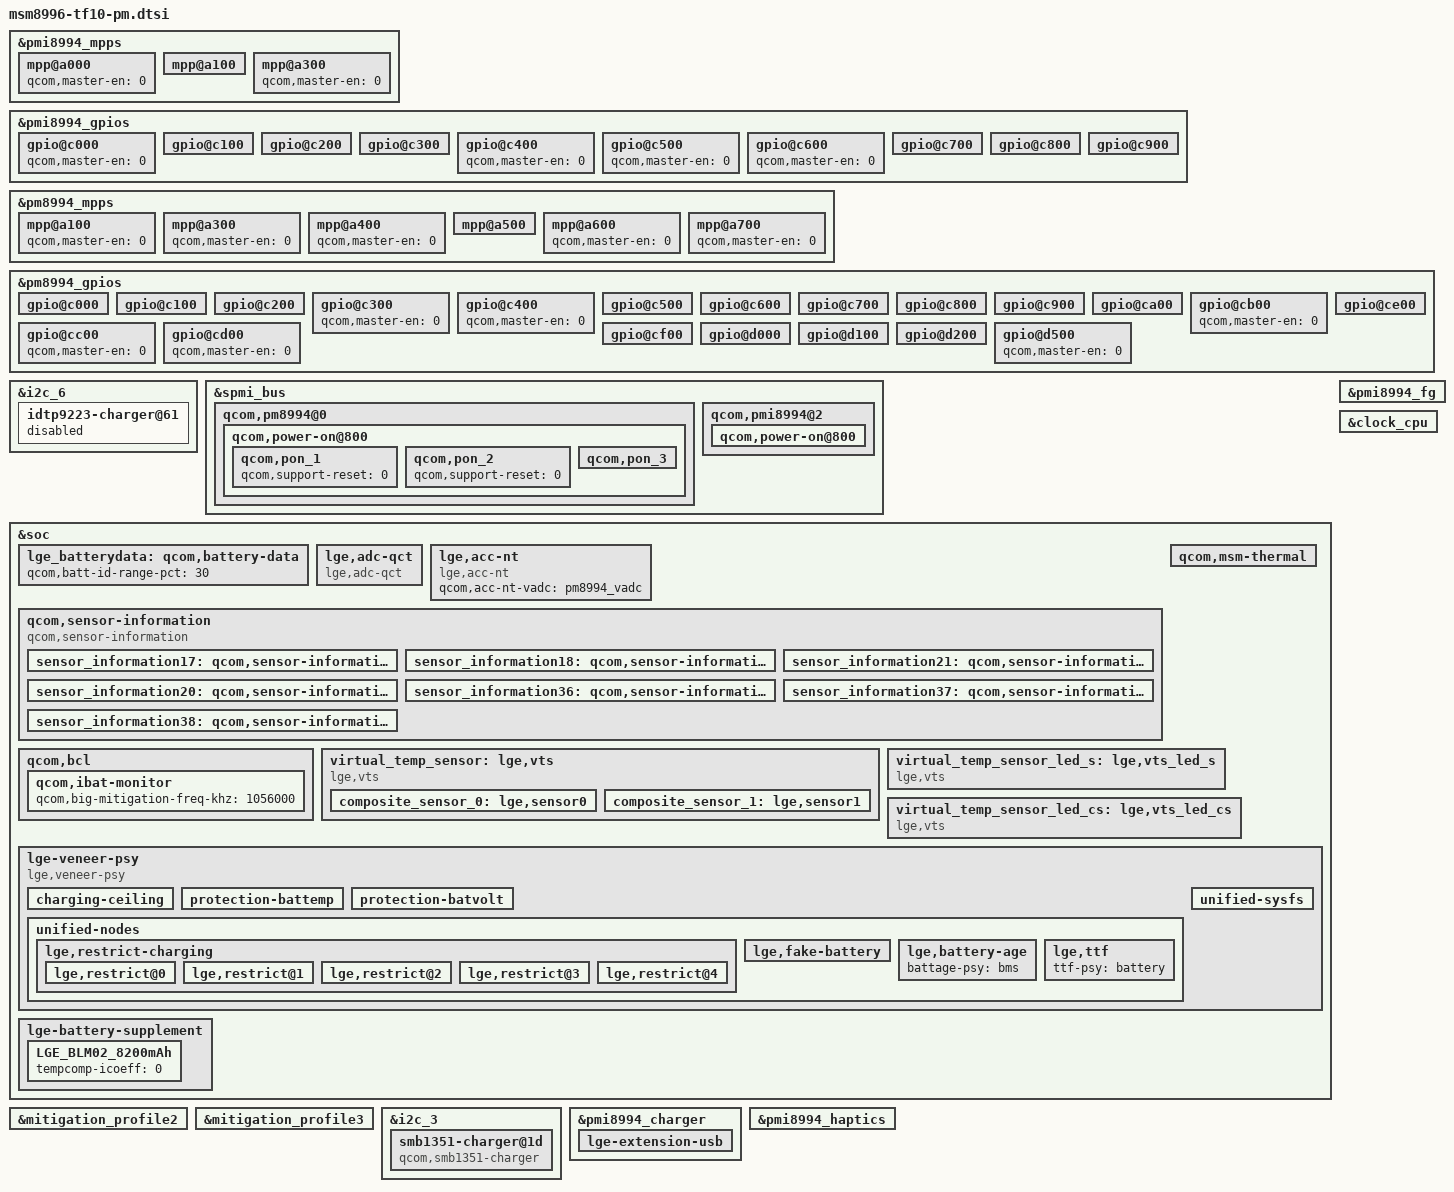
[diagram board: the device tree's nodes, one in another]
/* Copyright (c) 2015, The Linux Foundation. All rights reserved.
 *
 * This program is free software; you can redistribute it and/or modify
 * it under the terms of the GNU General Public License version 2 and
 * only version 2 as published by the Free Software Foundation.
 *
 * This program is distributed in the hope that it will be useful,
 * but WITHOUT ANY WARRANTY; without even the implied warranty of
 * MERCHANTABILITY or FITNESS FOR A PARTICULAR PURPOSE.  See the
 * GNU General Public License for more details.
 */

&pmi8994_mpps {
/* Must not define the mpp(mpp 3) on here */
	mpp@a000 {	/* MPP 1 - NC */
		qcom,master-en = <0>;		/* Disable MPP */
		status = "okay";
	};

	mpp@a100 { /* MPP 2 - FLASH_STROBE_TRIG */
		qcom,mode = <0>;			/* Digital input */
		qcom,invert = <1>;			/* Enable invert */
		qcom,vin-sel = <2>;			/* Vin 2 */
		qcom,src-sel = <0>;			/* Constant */
		qcom,master-en = <1>;		/* Enable MPP */
		status = "okay";
	};

	mpp@a300 { /* MPP 4 - NC */
		qcom,master-en = <0>;		/* Disable MPP */
		status = "okay";
	};
};

&pmi8994_gpios {
	gpio@c000 { /* GPIO 1 - NC */
		qcom,master-en = <0>;		/* Disable GPIO */
		status = "okay";
	};

	gpio@c100 { /* GPIO 2 - HIFI_RESET_N */
		qcom,mode = <1>;			/* Digital output*/
		qcom,pull = <0>;			/* Pull down 30uA */
		qcom,vin-sel = <2>;			/* VIN2 */
		qcom,src-sel = <0>;			/* Constant */
		qcom,invert = <1>;			/* Enable Invert */
		qcom,out-strength = <1>;	/* Low */
		qcom,master-en = <1>;		/* Enable GPIO */
		status = "okay";
	};

	gpio@c200 {	/* GPIO 3 SPKR_AMP_EN2 */
		qcom,mode = <1>;			/* Digital output*/
		qcom,pull = <4>;			/* Pull down */
		qcom,vin-sel = <2>;			/* VIN2 */
		qcom,src-sel = <0>;			/* Constant */
		qcom,invert = <0>;			/* Disable Invert */
		qcom,out-strength = <1>;	/* Low */
		qcom,master-en = <1>;		/* Enable GPIO */
		status = "okay";
	};

	gpio@c300 { /* GPIO 4 - WLC_OFF */
		qcom,mode = <1>;			/* Digital output*/
		qcom,pull = <4>;			/* Pull down */
		qcom,vin-sel = <2>;			/* VIN2 */
		qcom,src-sel = <0>;			/* Constant */
		qcom,invert = <0>;			/* Disable Invert */
		qcom,out-strength = <1>;	/* Low */
		qcom,master-en = <1>;		/* Enable GPIO */
		status = "okay";
	};

	gpio@c400 { /* GPIO 5 - NC */
		qcom,master-en = <0>;		/* Disable GPIO */
		status = "okay";
	};

	gpio@c500 { /* GPIO 6 - NC */
		qcom,master-en = <0>;		/* Disable GPIO */
		status = "okay";
	};

	gpio@c600 { /* GPIO 7 - NC */
		qcom,master-en = <0>;		/* Disable GPIO */
		status = "okay";
	};

	gpio@c700 { /* GPIO 8 - NC */
		qcom,master-en = <0>;		/* Disable GPIO */
		status = "okay";
	};

	gpio@c800 { /* GPIO 9 - NC */
		qcom,master-en = <0>;		/* Disable GPIO */
		status = "okay";
	};

	gpio@c900 { /* GPIO 10 - NC */
		qcom,master-en = <0>;		/* Disable GPIO */
		status = "okay";
	};
};

&pmi8994_gpios {
	gpio@c300 { /* GPIO 4 - NC */
		qcom,master-en = <0>;		/* Disable GPIO */
		status = "okay";
	};

	gpio@c700 {
	  qcom,mode = <1>;
	  qcom,pull = <4>;
	  qcom,vin-sel = <2>;
	  qcom,src-sel = <0>;
	  qcom,invert = <0>;
	  qcom,master-en = <1>;
	  status = "okay";
	 };

	gpio@c800 {
	  qcom,mode = <1>;
	  qcom,output-type = <0>;
	  qcom,invert = <1>;
	  qcom,vin-sel = <0>;
	  qcom,src-sel = <0>;
	  qcom,out-strength = <1>;
	  qcom,master-en = <1>;
	  status = "okay";
	 };

	 gpio@c900 {
	  qcom,mode = <0>;
	  qcom,vin-sel = <2>;
	  qcom,src-sel = <0>;
	  qcom,master-en = <1>;
	  status = "okay";
	 };

};

&pm8994_mpps {
/* Must not define the mpps(mpp 1 and 3) on here */
	mpp@a100 { /* MPP 2 - NC */
		qcom,master-en = <0>;		/* Disable MPP */
		status = "okay";
	};

	mpp@a300 { /* MPP 4 - NC */
		qcom,master-en = <0>;		/* Disable MPP */
		status = "okay";
	};

	mpp@a400 { /* MPP 5 - NC */
		qcom,master-en = <0>;		/* Disable MPP */
		status = "okay";
	};

	mpp@a500 { /* MPP 6 - STAT_SMB1350 */
		qcom,mode = <1>;			/* Digital output */
		qcom,invert = <0>;			/* Enable invert */
		qcom,vin-sel = <2>;			/* Vin 2 */
		qcom,src-sel = <0>;			/* Constant */
		qcom,out-strength = <1>;	/* Low */
		qcom,master-en = <1>;		/* Enable MPP */
		status = "okay";
	};

	mpp@a600 { /* MPP 7 - NC */
		qcom,master-en = <0>;		/* Disable MPP */
		status = "okay";

	};

	mpp@a700 { /* MPP 8 - NC */
		qcom,master-en = <0>;		/* Disable MPP */
		status = "okay";
	};
};

&pm8994_gpios {
/* Gpio 1 and 3 is set on relevant usb-type-c */
/* Must not define the gpios(gpio 20 and 21) on here */
	gpio@c000 { /* GPIO 1 VCONN */
		qcom,mode = <1>;		/* Digital output */
		qcom,pull = <0>;
		qcom,vin-sel = <2>;		/* VIN2 */
		qcom,src-sel = <2>;		/* GPIO */
		qcom,master-en = <1>;		/* Enable GPIO */
		status = "okay";
	};

	gpio@c100 { /* GPIO 2 - VOL_UP_EN */
		qcom,mode = <0>;			/* Digital input */
		qcom,pull = <0>;			/* Pull up 30uA */
		qcom,vin-sel = <2>;			/* Vin 2 */
		qcom,src-sel = <0>;			/* Constant */
		qcom,invert = <1>;			/* Enable Invert */
		qcom,out-strength = <1>;	/* Low */
		qcom,master-en = <1>;		/* Enable GPIO */
		status = "okay";
	};

	gpio@c200 { /* GPIO 3 SBU_SEL */
		qcom,mode = <1>;		/* Digital output */
		qcom,output-type = <0>;		/* MOS logic */
		qcom,vin-sel = <0>;		/* VPH_PWR */
		qcom,src-sel = <0>;		/* Constant */
		qcom,out-strength = <1>;	/* High drive strength */
		qcom,master-en = <1>;		/* Enable GPIO */
		status = "okay";
	};

	gpio@c300 { /* GPIO 4 - NC */
		qcom,master-en = <0>;		/* Disable GPIO */
		status = "okay";
	};

	gpio@c400 { /* GPIO 5 - NC */
		qcom,master-en = <0>;		/* Disable GPIO */
		status = "okay";
	};

	gpio@c500 { /* GPIO 6 - CAM0_AVDD_EN */
		qcom,mode = <1>;			/* Digital output */
		qcom,pull = <4>;			/* Pull down */
		qcom,vin-sel = <2>;			/* Vin 2 */
		qcom,src-sel = <0>;			/* Constant */
		qcom,invert = <0>;			/* Disable Invert */
		qcom,out-strength = <1>;	/* Low */
		qcom,master-en = <1>;		/* Enable GPIO */
		status = "okay";
	};

	gpio@c600 { /* GPIO 7 - CAM1_AVDD_EN */
		qcom,mode = <1>;			/* Digital output */
		qcom,pull = <4>;			/* Pull down */
		qcom,vin-sel = <2>;			/* Vin 2 */
		qcom,src-sel = <0>;			/* Constant */
		qcom,invert = <0>;			/* Disable Invert */
		qcom,out-strength = <1>;	/* Low */
		qcom,master-en = <1>;		/* Enable GPIO */
		status = "okay";
	};

	gpio@c700 { /* GPIO 8 - WLAN_POWER_EN */
		qcom,mode = <1>;			/* Digital output */
		qcom,pull = <4>;			/* Pull down */
		qcom,output-type = <0>;		/* CMOS logic */
		qcom,vin-sel = <2>;			/* Vin2 */
		qcom,src-sel = <0>;			/* Constant */
		qcom,invert = <0>;			/* Disable Invert */
		qcom,out-strength = <1>;	/* Low */
		qcom,master-en = <1>;		/* Enable GPIO */
		status = "okay";
	};

	gpio@c800 { /* GPIO 9 - Rome 3.3V control */
		qcom,mode = <1>;		/* Digital output */
		qcom,output-type = <0>;		/* CMOS logic */
		qcom,invert = <1>;		/* Output high */
		qcom,vin-sel = <0>;		/* VPH_PWR */
		qcom,src-sel = <0>;		/* Constant */
		qcom,out-strength = <1>;	/* High drive strength */
		qcom,master-en = <1>;		/* Enable GPIO */
		status = "okay";
	};

	gpio@c900 { /* GPIO 10 - HIFI_MODE2 */
		qcom,mode = <1>;			/* Digital output */
		qcom,pull = <4>;			/* Pull down */
		qcom,vin-sel = <2>;			/* Vin2 */
		qcom,src-sel = <0>;			/* Constant */
		qcom,invert = <0>;			/* Disable Invert */
		qcom,out-strength = <1>;	/* Low */
		qcom,master-en = <1>;		/* Enable GPIO */
		status = "okay";
	};

	gpio@ca00 { /* GPIO 11 - HIFI_LDO_SW */
		qcom,mode = <1>;			/* Digital output */
		qcom,pull = <4>;			/* Pull down */
		qcom,vin-sel = <2>;			/* Vin 2 */
		qcom,src-sel = <0>;			/* Constant */
		qcom,invert = <0>;			/* Invert */
		qcom,out-strength = <1>;	/* Low */
		qcom,master-en = <1>;		/* Enable GPIO */
		status = "okay";
	};

	gpio@cb00 { /* GPIO 12 - NC */
		qcom,master-en = <0>;		/* Disable GPIO */
		status = "okay";
	};

	gpio@cc00 { /* GPIO 13 - NC */
		qcom,master-en = <0>;		/* Disable GPIO */
		status = "okay";
	};

	gpio@cd00 { /* GPIO 14 - NC */
		qcom,master-en = <0>;		/* Disable GPIO */
		status = "okay";
	};

	gpio@ce00 { /* GPIO 15 - CODEC_MCLK */
		qcom,mode = <1>;			/* Digital output */
		qcom,pull = <5>;			/* No pull */
		qcom,output-type = <0>;		/* CMOS logic */
		qcom,vin-sel = <2>;			/* Vin 2 */
		qcom,src-sel = <2>;			/* Function 2 */
		qcom,out-strength = <2>;	/* Middle */
		qcom,master-en = <1>;		/* Enable GPIO */
		status = "okay";
	};

	gpio@cf00 { /* GPIO 16 - PMI_CLK_IN */
		qcom,mode = <1>;			/* Digital output */
		qcom,pull = <5>;			/* No pull */
		qcom,output-type = <0>;		/* CMOS logic */
		qcom,vin-sel = <2>;			/* Vin 2 */
		qcom,src-sel = <2>;			/* Function 2 */
		qcom,invert = <0>;			/* Disable Invert */
		qcom,out-strength = <3>;	/* High */
		qcom,master-en = <1>;		/* Enable GPIO */
		status = "okay";
	};

	gpio@d000 { /* GPIO 17 - AOD_RTC */
		qcom,mode = <1>;			/* Digital output */
		qcom,pull = <5>;			/* No pull */
		qcom,output-type = <0>;		/* CMOS logic */
		qcom,vin-sel = <2>;			/* Vin 2 */
		qcom,src-sel = <3>;			/* Function 2 */
		qcom,out-strength = <2>;	/* Middle */
		qcom,master-en = <1>;		/* Enable GPIO */
		status = "okay";
	};

	gpio@d100 { /* GPIO 18 - WIFI_SLEEP_CLK */
		qcom,mode = <1>;			/* Digital output */
		qcom,output-type = <0>;		/* CMOS logic */
		qcom,invert = <0>;			/* Output low initially */
		qcom,vin-sel = <2>;			/* VIN 2 */
		qcom,src-sel = <3>;			/* Function 2 */
		qcom,out-strength = <2>;	/* Medium */
		qcom,master-en = <1>;		/* Enable GPIO */
		status = "okay";
	};

	gpio@d200 { /* GPIO 19 - BT_POWER_ON */
		qcom,mode = <1>;			/* Digital output */
		qcom,pull = <4>;			/* Pull down */
		qcom,vin-sel = <2>;			/* Vin2 */
		qcom,src-sel = <0>;			/* Constant */
		qcom,invert = <0>;			/* Disable Invert */
		qcom,out-strength = <1>;	/* Low */
		qcom,master-en = <1>;		/* Enable GPIO */
		status = "okay";
	};
	gpio@d500 { /* GPIO 22 - NC */
		qcom,master-en = <0>;		/* Disable GPIO */
		status = "okay";
	};
};

&i2c_6 {
        idtp9223-charger@61 {
                status = "disabled";
        };
};

&spmi_bus {
	qcom,pm8994@0 {
		 qcom,power-on@800 {
			 qcom,s3-debounce = <128>;
			 qcom,s3-src = "kpdpwr-and-resin";
			 qcom,pon_1 {  /* KPD_PWR_N */
				  status = "ok";
				  qcom,support-reset = <0>;
			 };
			 qcom,pon_2 {  /* RESIN_N */
				  status = "ok";
				  qcom,support-reset = <0>;
			 };
			 qcom,pon_3 {  /* KPD_PWR_N AND RESIN_N */
				  status = "ok";
				  qcom,support-reset = <1>;
				  qcom,s1-timer = <6720>;
				  qcom,s2-timer = <2000>;
				  qcom,s2-type = <7>;
			 };
		 };
	};

	qcom,pmi8994@2 {
		qcom,power-on@800 {
			qcom,s3-debounce = <128>;
			qcom,s3-src = "kpdpwr-and-resin";
		};
	};
};

&soc {
	lge_batterydata: qcom,battery-data {
		qcom,batt-id-range-pct = <30>;
		#include "../LGE_BLM02_8200mAh.dtsi"
	};

	lge,adc-qct {
		compatible = "lge,adc-qct";
		qcom,pm_adc-vadc = <&pm8994_vadc>;
		qcom,pmi_adc-vadc = <&pmi8994_vadc>;
		lge,gpio-sbu-en = <&tlmm 90 0>;
		lge,xo_therm_chan = <0x72>;
		lge,pa0_therm_chan = <0x75>;
		lge,pa1_therm_chan = <0x77>;
		lge,bd1_therm_chan = <0xff>;
		lge,bd2_therm_chan = <0x74>;
		lge,batt_therm_chan = <0xff>;
		lge,usb_id_chan = <0x39>;
	};

	lge,acc-nt {
		compatible = "lge,acc-nt";
		qcom,acc-nt-vadc = <&pm8994_vadc>;
	};

	qcom,sensor-information {
		compatible = "qcom,sensor-information";

		sensor_information17: qcom,sensor-information-17 {
			qcom,sensor-type = "adc";
			qcom,sensor-name = "bd_therm_1";
		};

		sensor_information18: qcom,sensor-information-18 {
			qcom,sensor-type = "adc";
			qcom,sensor-name = "bd_therm_2";
		};

		sensor_information21: qcom,sensor-information-21 {
			qcom,sensor-type = "adc";
			qcom,sensor-name = "xo_therm";
		};
		sensor_information20: qcom,sensor-information-20 {
			qcom,sensor-type = "adc";
			qcom,sensor-name = "vts";
			qcom,scaling-factor = <10>;
		};
		sensor_information36: qcom,sensor-information-36 {
			qcom,sensor-type = "adc";
			qcom,sensor-name = "battery";
			qcom,scaling-factor = <1000>;
		};
		sensor_information37: qcom,sensor-information-37 {
			qcom,sensor-type = "adc";
			qcom,sensor-name = "led_sensor";
			qcom,scaling-factor = <1>;
		};

		sensor_information38: qcom,sensor-information-38 {
			qcom,sensor-type = "adc";
			qcom,sensor-name = "led_c_sensor";
			qcom,scaling-factor = <1>;
		};
	};

	qcom,msm-thermal {
		qcom,poll-ms = <50>;
		qcom,limit-temp = <80>;
		qcom,core-limit-temp = <90>;
		qcom,disable-gfx-phase-ctrl;
		qcom,disable-psm;
		qcom,disable-ocr;
		qcom,disable-cx-phase-ctrl;
		qcom,freq-mitigation-temp = <103>;
		qcom,freq-mitigation-temp-hysteresis = <15>;
		qcom,freq-mitigation-value = <1036800>;
		qcom,big-hotplug-temp = <105>;
		qcom,big-hotplug-temp-hysteresis = <40>;
	};

	qcom,bcl {
		qcom,bcl-soc-hotplug-list = <>;
		qcom,bcl-freq-control-list = <&CPU0 &CPU1 &CPU2 &CPU3>;
	};

	/* vts, 0.620*XO + 0.116*BD2 + 6.94 */
	virtual_temp_sensor: lge,vts {
		compatible = "lge,vts";
		lge,index = <101>;
		qcom,vts-vadc = <&pm8994_vadc>;
		lge,scaling-factor = <10>;
		lge,constant-milli = <6940>;
		composite_sensor_0: lge,sensor0 {
			label = "xo_therm";
			channel = <0x72>;
			weight-milli = <620>;
		};
		composite_sensor_1: lge,sensor1 {
			label = "bd_therm_2";
			channel = <0x74>;
			weight-milli = <116>;
		};
	};

	virtual_temp_sensor_led_s: lge,vts_led_s {
		compatible = "lge,vts";
		lge,name = "led_sensor";
		lge,index = <102>;
		qcom,vts-vadc = <&pm8994_vadc>;
		lge,scaling-factor= <1>;
	};

	virtual_temp_sensor_led_cs: lge,vts_led_cs {
		compatible = "lge,vts";
		lge,name = "led_c_sensor";
		lge,index = <103>;
		qcom,vts-vadc = <&pm8994_vadc>;
		lge,scaling-factor= <1>;
	};

};

&mitigation_profile2 {
	qcom,temperature-sensor = <&sensor_information9>;
	qcom,boot-frequency-mitigate;
	qcom,hotplug-mitigation-enable;
};

&mitigation_profile3 {
	qcom,temperature-sensor = <&sensor_information11>;
	qcom,boot-frequency-mitigate;
	qcom,hotplug-mitigation-enable;
};

&soc {
        qcom,msm-thermal {
                qcom,freq-mitigation-value = <1056000>;
        };
        qcom,bcl {
                qcom,ibat-monitor {
                        qcom,big-mitigation-freq-khz = <1056000>;
                };
        };
};

&soc {
    lge-veneer-psy {
        compatible = "lge,veneer-psy";
        status = "ok";

        charging-ceiling {
            /*             iusb ibat  : 0 means UNCEILING */
            lge,unknown = <   0    0>;
            lge,float   = < 500  500>;
            lge,none    = <   0    0>;

            lge,dcp     = <1800 3000>;
            lge,10k     = <3000    0>;
            lge,22k     = <1500    0>;
            lge,qc2     = <1800 3000>;
            lge,qc3     = <1800 3000>;

            lge,usb2    = < 500  500>;
            lge,usb3    = < 900  900>;
            lge,cdp     = <1500 1500>;
            lge,pd      = <   0    0>;

            lge,56k     = <1500  500>;
            lge,130k    = <1500  500>;
            lge,910k    = <1500  500>;
        };

        protection-battemp {
            lge,threshold-degc-upto-cool = <30>;
            lge,threshold-degc-upto-good = <120>;
            lge,threshold-degc-upto-warm = <450>;
            lge,threshold-degc-upto-hot = <550>;
            lge,threshold-degc-downto-warm = <520>;
            lge,threshold-degc-downto-good = <430>;
            lge,threshold-degc-downto-cool = <100>;
            lge,threshold-degc-downto-cold = <0>;

            lge,period-ms-emergency = <10000>;
            lge,period-ms-warning   = <30000>;
            lge,period-ms-normal    = <60000>;

            // parameters for warning status cool and warm
            lge,cool-mv-alert   = <4000>;
            lge,cool-ma-alert   = <800>;        // fixed 500 mA over 4V(0.2C)   // tf10 fixed 800mA            (0.1C)
            lge,cool-ma-pct     = <10>;         // means 0.1C rate under 4V     // tf10 cool ibat set to 800mA (0.1C)

            lge,warm-mv-float   = <4000>;
            lge,warm-ma-pct     = <10>;         // means 0.1C rate under 4V     // tf10 warm ibat set to 800mA (0.1C)

            // parameters for battery protection at chilly status
            lge,chilly-status-support;
            lge,chilly-degc-lowerbound = <100>;
            lge,chilly-degc-upperbound = <150>;
            lge,chilly-mv-alert    = <4000>;
            lge,chilly-mv-bound     = <200>;
            lge,chilly-ma-alert    = <2400>;    // fixed 2400mA over 4V         // tf10 fixed 550mA             (0.2C)
            lge,chilly-ma-pct      = <30>;      // means 0.3C rate under 4V     // tf10 chilly ibat set to 2400mA (0.4C)
        };

        protection-batvolt {
            lge,threshold-vbat-limit = <4250>;
            lge,threshold-vbat-clear = <4200>;
	    lge,threshold-ibat-pct = <70>;	// means 0.7C rate
	    lge,threshold-cv-ibat-pct = <100>;	// means 0.1C rate

            lge,step-ibat-ma = <100>;
            lge,step-poll-ms = <5000>;
        };

        unified-nodes {
            lge,feature-charging-parallel = <0>;
            lge,feature-charging-highspeed = <0>;

            lge,restrict-charging {
                // restrict-values 0 means UNCEILING

                lge,restrict@0 {
                    restrict-name = "LCD";
                    restrict-type = "ibat";
                    restrict-commands = "ON", "OFF";
                    restrict-values = <1800      0>;
                };
                lge,restrict@1 {
                    restrict-name = "CALL";
                    restrict-type = "ibat";
                    restrict-commands = "ON", "OFF";
                    restrict-values = < 0      0>;
                };
                lge,restrict@2 {
                    restrict-name = "UHDREC";
                    restrict-type = "ibat";
                    restrict-commands = "ON", "OFF";
                    restrict-values = < 0      0>;
                };
                lge,restrict@3 {
                    restrict-name = "WFD";
                    restrict-type = "ibat";
                    restrict-commands = "ON", "OFF";
                    restrict-values = < 0      0>;
                };
                lge,restrict@4 {
                    restrict-name = "TDMB";
                    restrict-type = "ibat";
                    restrict-commands = "MODE1", "MODE2", "OFF";
                    restrict-values = <    0      0      0>;
                };
            };

            lge,fake-battery {
                fakebatt-psy = "bms";       // What 'psy' does implement(or support) the fake battery?
                fakebatt-temperature = <400>;
                fakebatt-mvoltage = <4000>;
                fakebatt-capacity = <80>;
            };

            lge,battery-age {
                battage-psy = "bms";        // What 'psy' does implement(or support) the battery age?
            };

            lge,ttf {
                ttf-psy = "battery";	// What 'psy' does implement(or support) the time to full now?
            };
        };

        unified-sysfs {
            lge,symlink-map =
                /* group , user_node, kernel node */
                /* Charger */
                "charger",                     "ac_online", "NULL",
                "charger",                    "usb_online", "/sys/class/power_supply/usb/online",   /* TODO */
                "charger",                       "present", "/sys/class/power_supply/usb/present",
                "charger",                    "wlc_online", "/sys/class/power_supply/wireless/online",
                "charger",                          "type", "/sys/class/power_supply/usb/real_type",
		"charger",                   "usb_pd_type", "/sys/class/power_supply/usb/real_type",
                "charger",                      "time_out", "/sys/class/power_supply/battery/safety_timer_enabled",
                "charger",              "charging_enabled", "/sys/devices/platform/lge-unified-nodes/charging_enable",
                "charger",                  "ibat_current", "/sys/class/power_supply/battery/current_now",
                "charger",                  "ichg_current", "/sys/class/power_supply/usb/current_max",
                "charger",                  "iusb_control", "NULL",
                "charger",            "thermal_mitigation", "NULL",
                "charger",        "wlc_thermal_mitigation", "NULL",
                "charger",       "usb_parallel_chg_status", "NULL",
				"charger", "parallel_current_max", "/sys/class/power_supply/parallel/current_max",
                "charger", "usb_parallel_charging_enabled", "NULL",
                "charger", "factory_parallel_charger_test", "/sys/devices/platform/lge-unified-nodes/support_fastpl",
                "charger",            "moisture_detection", "/sys/class/power_supply/usb/moisture_detected",
                "charger",           "restricted_charging", "/sys/devices/platform/lge-unified-nodes/charging_restriction",
                "charger",              "ibat_max_current", "/sys/class/power_supply/battery/constant_charge_current_max",
                "charger",                       "chgstep", "/sys/devices/platform/lge-unified-nodes/charging_step",
                "charger",               "connection_type", "NULL",
                "charger",                       "fastchg", "/sys/devices/platform/lge-unified-nodes/charger_highspeed",
                "charger",         "input_current_settled", "/sys/class/power_supply/battery/input_current_max",
                "charger",             "input_current_max", "/sys/class/power_supply/battery/input_current_max",
                "charger",            "store_demo_enabled", "NULL",
                "charger",     "wireless_charging_enabled", "NULL",
                "charger",                 "input_suspend", "/sys/class/power_supply/battery/input_suspend",
                "charger",                  "incompatible", "/sys/devices/platform/lge-unified-nodes/charger_incompatible",
                "charger",                    "hvdcp_fake", "/sys/devices/platform/lge-unified-nodes/fake_hvdcp",
                "charger",               "usb_current_max", "/sys/devices/platform/lge-unified-nodes/fake_sdpmax",
                "charger",               "fastchg_support", "/sys/devices/platform/lge-unified-nodes/support_fastchg",
                "charger",                    "usbid_type", "/sys/class/power_supply/usb/resistance_id",
                "charger",                 "ccd_batchg_en", "/sys/devices/platform/lge-unified-nodes/ccd_batchg_en",
                "charger",             "ccd_input_suspend", "/sys/devices/platform/lge-unified-nodes/ccd_input_suspend",
                "charger",                       "ccd_icl", "/sys/devices/platform/lge-unified-nodes/ccd_icl",
                "charger",                       "ccd_fcc", "/sys/devices/platform/lge-unified-nodes/ccd_fcc",
                "charger",                    "ccd_vfloat", "/sys/devices/platform/lge-unified-nodes/ccd_vfloat",
                "charger",                     "aicl_done", "/sys/devices/platform/lge-unified-nodes/aicl_done",
                /* ADC/MPP */
                "adc",              "thermal", "/sys/class/thermal/",
                "adc",             "xo_therm", "/sys/class/hwmon/hwmon2/device/xo_therm",
                "adc",           "batt_therm", "/sys/class/power_supply/battery/temp",
                "adc",              "batt_id", "/sys/devices/platform/lge-unified-nodes/battery_valid",
                "adc",            "pa_therm0", "/sys/class/hwmon/hwmon2/device/pa_therm0",
                "adc",            "pa_therm1", "NULL",
                "adc",           "quiet_therm","/sys/class/hwmon/hwmon2/device/quiet_therm",
                "adc",               "usb_in", "/sys/class/power_supply/usb/voltage_now",
                "adc",                "vcoin", "/sys/class/hwmon/hwmon2/device/vcoin",
                "adc",              "vph_pwr", "/sys/class/hwmon/hwmon2/device/vph_pwr",
                "adc",               "usb_id", "/sys/devices/platform/lge-unified-nodes/charger_usbid",
                "adc",             "usb_edge", "NULL",
                "adc",                 "pmic", "/sys/class/thermal/thermal_zone2/temp",
                "adc",                  "vts", "/sys/class/thermal/thermal_zone38/temp",
                /* Battery */
                "battery",         "capacity", "/sys/class/power_supply/battery/capacity",
                "battery",           "health", "/sys/class/power_supply/battery/health",
                "battery",          "present", "/sys/class/power_supply/battery/present",
                "battery",      "pseudo_batt", "/sys/devices/platform/lge-unified-nodes/fake_battery",
                "battery",           "status", "/sys/class/power_supply/battery/status",
                "battery",       "status_raw", "NULL",
                "battery",             "temp", "/sys/class/power_supply/battery/temp",
                "battery",    "valid_batt_id", "/sys/devices/platform/lge-unified-nodes/battery_valid",
                "battery",      "voltage_now", "/sys/class/power_supply/battery/voltage_now",
                "battery",          "vzw_chg", "/sys/devices/platform/lge-unified-nodes/charger_verbose",
                "battery",     "raw_capacity", "/sys/class/power_supply/bms/capacity",
                "battery",        "condition", "/sys/devices/platform/lge-unified-nodes/battery_condition",
                "battery",      "battery_age", "/sys/devices/platform/lge-unified-nodes/battery_age",
                "battery","battery_age_level", "/sys/devices/platform/lge-unified-nodes/battery_age",
                "battery",            "cycle", "/sys/class/power_supply/bms/battery_cycle",
                "battery",     "battery_type", "/sys/class/power_supply/bms/battery_type",
                "battery",      "charge_full", "/sys/class/power_supply/bms/charge_full",
                "battery",   "charge_now_raw", "/sys/class/power_supply/bms/charge_now_raw",
                "battery",     "ttf_capacity", "/sys/devices/platform/lge-unified-nodes/ttf_capacity",
                "battery", "time_to_full_now", "/sys/devices/platform/lge-unified-nodes/time_to_full_now",
                /* LCD Backlight */
                "lcd",           "brightness", "/sys/class/backlight/panel0-backlight/brightness",
                "lcd",       "max_brightness", "/sys/class/backlight/panel0-backlight/max_brightness",
                "lcd_ex",        "brightness", "NULL",
                "lcd_ex",    "max_brightness", "NULL",
                /* KEY LED */
                "key_led",   "red_brightness", "/sys/class/leds/red/brightness",
                "key_led", "green_brightness", "/sys/class/leds/green/brightness",
                "key_led",  "blue_brightness", "/sys/class/leds/blue/brightness",
                "key_led",  "setting",         "/sys/class/lg_rgb_led/use_patterns/setting",
                /* CPU */
                "cpu",       "cpu_idle_modes", "NULL",
                /* GPU */
                "gpu",                 "busy", "/sys/class/kgsl/kgsl-3d0/gpubusy",
                "gpu",               "gpuclk", "/sys/class/kgsl/kgsl-3d0/gpuclk",
                /* PLATFORM */
                "platform",       "speed_bin", "NULL",
                "platform",         "pvs_bin", "NULL",
                "platform",     "power_state", "/sys/power/autosleep",
                "platform",   "poweron_alarm", "/sys/module/qpnp_rtc/parameters/poweron_alarm",
                "platform",         "pcb_rev", "/sys/class/hwmon/hwmon2/device/mpp2_pcb_rev",
                "platform",       "smpl_boot", "/sys/module/lge_smpl_count/parameters/smpl_boot",
                /* testmode */
                "testmode",            "temp", "/sys/class/power_supply/battery/temp",
                "testmode",     "voltage_now", "/sys/class/power_supply/battery/voltage_now",
                "testmode",          "usb_id", "/sys/devices/platform/lge-unified-nodes/charger_usbid",
                "testmode",         "batt_id", "/sys/devices/platform/lge-unified-nodes/battery_valid",
                "testmode",         "fuelval", "/sys/class/power_supply/battery/capacity",
                "testmode",        "xo_therm", "/sys/class/hwmon/hwmon2/device/xo_therm",
                "testmode",          "charge", "/sys/class/power_supply/battery/battery_charging_enabled",
                "testmode",          "chcomp", "/sys/devices/platform/lge-unified-nodes/charging_completed",
                "testmode",           "usbin", "/sys/class/power_supply/usb/voltage_now",
                "testmode",       "pa_therm0", "/sys/class/hwmon/hwmon2/device/pa_therm0",
                "testmode",       "pa_therm1", "NULL",
                "testmode",       "bd_therm2", "/sys/class/hwmon/hwmon2/device/quiet_therm",
                "testmode",           "vcoin", "/sys/class/hwmon/hwmon2/device/vcoin",
                "testmode",         "vph_pwr", "/sys/class/hwmon/hwmon2/device/vph_pwr",
                "testmode",     "current_now", "/sys/class/power_supply/battery/current_now",
                "testmode",     "current_max", "/sys/class/power_supply/usb/current_max",
                "testmode",         "pcb_rev", "/sys/class/hwmon/hwmon2/device/mpp2_pcb_rev",
                "testmode",      "chgmodeoff", "/sys/class/power_supply/battery/input_suspend",
                "testmode",         "fuelrst", "/sys/class/power_supply/battery/present",
                "testmode",        "rtc_time", "/dev/rtc0",
                "testmode",           "pmrst", "NULL",
                "testmode",        "battexit", "/sys/class/power_supply/battery/present",
                "testmode",  "hardreset_mode", "NULL",
                /* ps feature*/
                "psfeature",     "vfps_ratio", "/sys/class/power/vfps/vfps_ratio",
                "psfeature",           "vfps", "/sys/class/power/vfps/vfps",
                "psfeature",      "vfps_fcnt", "/sys/class/power/vfps/vfps_fcnt",
                "psfeature",  "triton_policy", "/sys/class/power/triton/cur_policy",
                "psfeature",   "cancun_is_cm", "NULL",
                "regulator",       "vreg_bob", "/sys/devices/platform/soc/soc:lrmc/bob_mode";
        };
    };

	lge-battery-supplement {
	   capacity-mah-min = <8000>;
	   capacity-raw-full = <240>;
	   max-voltage-uv = <4350>;
	   lg-under-five-level-soc;

	   default-battery-name = "LGE_BLM02_8200mAh";
	   default-battery-kohm = <75>;

	/* format : (temp index) (temp delta) */
	   tempcomp-offset = <
	        (-300)    (-34)
	        (-200)    (-34)
	        (-190)    (-30)
	        (-180)    (-27)
	        (-170)    (-23)
	        (-160)    (-20)
	        (-150)    (-17)
	        (-100)    (0)
	        ( -50)    (8)
	        0         (15)
	        50        12
	        100       10
	        150       8
	        200       3
	        250       (-1)
	        300       (-4)
	        350       (-7)
	        400       (-6)
	        450       (-2)
	        500       (3)
	        550       (8)
	        600       (17)
	        700       (29)
	        800       (41)
	        900       (53)
	        >;
	   tempcomp-icoeff = <0>;
//	   tempcomp-qnovo-charging;

		/* overriding by battery type */
		LGE_BLM02_8200mAh {
			tempcomp-icoeff = <0>;
		};
	};
};

&i2c_3 {
	smb1351-charger@1d {
		compatible = "qcom,smb1351-charger";
		reg = <0x1d>;
		qcom,parallel-charger;
		qcom,float-voltage-mv = <4350>;
		qcom,recharge-mv = <100>;
		qcom,iterm-disabled;
	};
};

&pmi8994_charger {
	status = "ok";
	qcom,iterm-ma = <200>;
	qcom,fastchg-current-ma = <3000>;
	qcom,float-voltage-mv = <4350>;
	qcom,resume-delta-mv = <149>;
	qcom,bmd-pin-src="bpd_none";
	qcom,bms-psy-name = "bms";
	qcom,jeita-temp-hard-limit = <0>;
	/* move to main soc dtb */
	///delete-property/ qcom,charge-unknown-battery;
	///delete-property/ qcom,chg-inhibit-fg;
	qcom,parallel-usb-min-current-ma = <1400>;
	qcom,parallel-usb-9v-min-current-ma = <900>;
	qcom,parallel-main-chg-fcc-percent = <40>;
	qcom,charging-timeout-mins = <1536>;
	qcom,skip-usb-suspend-for-fake-battery;
	qcom,aicl-rerun-period-s = <180>;
	qcom,bmd-algo-disabled;
	qcom,usb_id-vadc = <&pm8994_vadc>;
	qcom,usbin-vadc = <&pmi8994_vadc>;
	qcom,default-hvdcp-icl-ma = <1800>;
	qcom,default-hvdcp3-icl-ma = <1800>;
	qcom,maximum-icl-ma = <3000>;
	qcom,acc-detect-gpio = <&tlmm 132 0>;
	qcom,enable-booster-gpio = <&pmi8994_gpios 9 0>;
	qcom,batt-life-cycle-fcc-ma = <3000 2900 2700 2500>;
	qcom,batt-life-cycle-vfloat = <4350 4340 4320 4300>;
	dpdm-supply = <&qusb_phy0>;
	lge,lge_otp_enable;
	lge-extension-usb {
		lge,usbid-56k-min-mvol = <150>;
		lge,usbid-56k-max-mvol = <280>;
		lge,usbid-130k-min-mvol = <330>;
		lge,usbid-130k-max-mvol = <500>;
		lge,usbid-910k-min-mvol = <750>;
		lge,usbid-910k-max-mvol = <900>;
		lge,usbid-open-min-mvol = <950>;
		lge,usbid-open-max-mvol = <1100>;
        lge,feature-moisture-charging = <0>;
    };
};

&pmi8994_fg {
	status = "ok";
	qcom,battery-data = <&lge_batterydata>;
	qcom,fg-cutoff-voltage-mv = <3400>;
	qcom,thermal-coefficients = [B7 85 B2 49 71 35];
	qcom,ext-sense-type;
	qcom,capacity-learning-feedback;
	qcom,resume-soc = <97>;
	qcom,resume-soc-raw = <247>;
	qcom,irq-volt-empty-mv = <2800>;
	qcom,fg-iterm-ma = <300>;
	qcom,fg-chg-iterm-ma = <200>;
	qcom,lge_batt_profile;
	qcom,vbat-estimate-diff-mv = <300>;
	qcom,fg-cc-cv-threshold-mv = <4340>;
	qcom,esr-pulse-tuning-en;
	qcom,fg-use-vbat-low-empty-soc;
	qcom,fg-reset-on-lockup;
	qcom,fg-cc-soc-limit-pct = <120>;
	qcom,fg-control-slope-limiter;
	qcom,fg-slope-limit-high-temp-chg = <6>;
	qcom,fg-slope-limit-high-temp-dischg = <6>;
	qcom,fg-slope-limit-low-temp-chg = <14>;
	qcom,fg-slope-limit-low-temp-dischg =<14>;
	qcom,fg-dischg-voltage-gain-ctrl;
	qcom,fg-dischg-voltage-gain-soc = <7 15 20>;
	qcom,fg-dischg-med-voltage-gain = <5 4 4>;
	qcom,fg-dischg-high-voltage-gain = <4 4 3>;
	qcom,fg-rconn-mohm = <0>;
	qcom,cl-max-limit-deciperc= <50>;
	qcom,fg-batt-life-cycle-set = <0 200 300 400>;
	qcom,fg-batt-life-cycle-offset = <0 2 7 11>;
	qcom,fg-batt-life-cycle-vfloat = <4350 4340 4320 4300>;
};

&pmi8994_haptics {
	status = "okay";
	qcom,actuator-type = <0>;
	qcom,play-mode = "direct";
	qcom,vmax-mv = <2200>;
	qcom,wave-shape = "sine";
	qcom,wave-play-rate-us = <4255>;
};

&clock_cpu {
	qcom,pwrcl-speedbin0-v0-f =
		<          0  0 >,
		<  307200000  1 >,
		<  384000000  2 >,
		<  460800000  3 >,
		<  537600000  4 >,
		<  614400000  5 >,
		<  691200000  6 >,
		<  768000000  7 >,
		<  844800000  8 >,
		<  902400000  9 >,
		<  979200000 10 >,
		< 1056000000 11 >,
		< 1132800000 12 >,
		< 1209600000 13 >,
		< 1286400000 14 >,
		< 1363200000 15 >,
		< 1440000000 16 >,
		< 1516800000 17 >,
		< 1593600000 18 >;
	qcom,pwrcl-speedbin1-v0-f =
		<          0  0 >,
		<  307200000  1 >,
		<  384000000  2 >,
		<  460800000  3 >,
		<  537600000  4 >,
		<  614400000  5 >,
		<  691200000  6 >,
		<  768000000  7 >,
		<  844800000  8 >,
		<  902400000  9 >,
		<  979200000 10 >,
		< 1056000000 11 >,
		< 1132800000 12 >,
		< 1209600000 13 >,
		< 1286400000 14 >,
		< 1363200000 15 >,
		< 1440000000 16 >,
		< 1516800000 17 >,
		< 1593600000 18 >;
	qcom,perfcl-speedbin0-v0-f =
		<          0  0 >,
		<  307200000  1 >,
		<  384000000  2 >,
		<  460800000  3 >,
		<  537600000  4 >,
		<  614400000  5 >,
		<  691200000  6 >,
		<  748800000  7 >,
		<  825600000  8 >,
		<  902400000  9 >,
		<  979200000 10 >,
		< 1056000000 11 >,
		< 1132800000 12 >,
		< 1209600000 13 >,
		< 1286400000 14 >,
		< 1363200000 15 >,
		< 1440000000 16 >,
		< 1516800000 17 >,
		< 1593600000 18 >,
		< 1670400000 19 >,
		< 1747200000 20 >,
		< 1824000000 21 >,
		< 1900800000 22 >,
		< 1977600000 23 >,
		< 2054400000 24 >,
		< 2150400000 25 >;
	qcom,perfcl-speedbin1-v0-f =
		<          0  0 >,
		<  307200000  1 >,
		<  384000000  2 >,
		<  460800000  3 >,
		<  537600000  4 >,
		<  614400000  5 >,
		<  691200000  6 >,
		<  748800000  7 >,
		<  825600000  8 >,
		<  902400000  9 >,
		<  979200000 10 >,
		< 1056000000 11 >,
		< 1132800000 12 >,
		< 1209600000 13 >,
		< 1286400000 14 >,
		< 1363200000 15 >,
		< 1440000000 16 >,
		< 1516800000 17 >,
		< 1593600000 18 >,
		< 1670400000 19 >,
		< 1747200000 20 >,
		< 1824000000 21 >,
		< 1900800000 22 >,
		< 1977600000 23 >,
		< 2054400000 24 >,
		< 2150400000 25 >;
	qcom,cbf-speedbin0-v0-f =
		<	   0  0 >,
		<  192000000  1 >,
		<  307200000  2 >,
		<  384000000  3 >,
		<  441600000  4 >,
		<  537600000  5 >,
		<  614400000  6 >,
		<  691200000  7 >,
		<  768000000  8 >,
		<  844800000  9 >,
		<  902400000 10 >,
		<  979200000 11 >,
		< 1056000000 12 >,
		< 1132800000 13 >,
		< 1190400000 14 >,
		< 1286400000 15 >,
		< 1363200000 16 >,
		< 1440000000 17 >,
		< 1516800000 18 >,
		< 1593600000 19 >;
	qcom,cbf-speedbin1-v0-f =
		<	   0  0 >,
		<  192000000  1 >,
		<  307200000  2 >,
		<  384000000  3 >,
		<  441600000  4 >,
		<  537600000  5 >,
		<  614400000  6 >,
		<  691200000  7 >,
		<  768000000  8 >,
		<  844800000  9 >,
		<  902400000 10 >,
		<  979200000 11 >,
		< 1056000000 12 >,
		< 1132800000 13 >,
		< 1190400000 14 >,
		< 1286400000 15 >,
		< 1363200000 16 >,
		< 1440000000 17 >,
		< 1516800000 18 >,
		< 1593600000 19 >;
};

